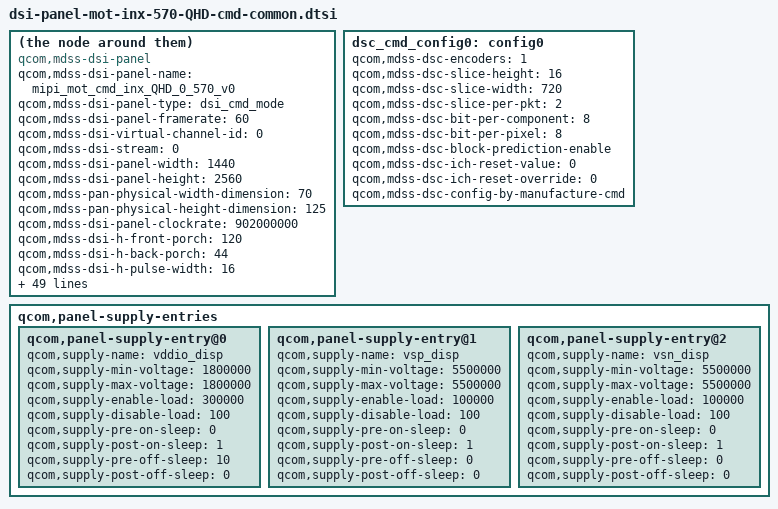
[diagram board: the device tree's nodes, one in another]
/* Copyright (c) 2015, The Linux Foundation. All rights reserved.
 *
 * This program is free software; you can redistribute it and/or modify
 * it under the terms of the GNU General Public License version 2 and
 * only version 2 as published by the Free Software Foundation.
 *
 * This program is distributed in the hope that it will be useful,
 * but WITHOUT ANY WARRANTY; without even the implied warranty of
 * MERCHANTABILITY or FITNESS FOR A PARTICULAR PURPOSE.  See the
 * GNU General Public License for more details.
 */

qcom,mdss-dsi-panel-name = "mipi_mot_cmd_inx_QHD_0_570_v0";
compatible = "qcom,mdss-dsi-panel";
qcom,mdss-dsi-panel-type = "dsi_cmd_mode";
qcom,mdss-dsi-panel-framerate = <60>;
qcom,mdss-dsi-virtual-channel-id = <0>;
qcom,mdss-dsi-stream = <0>;
qcom,mdss-dsi-panel-width = <1440>;
qcom,mdss-dsi-panel-height = <2560>;
qcom,mdss-pan-physical-width-dimension = <70>;
qcom,mdss-pan-physical-height-dimension = <125>;
qcom,mdss-dsi-panel-clockrate = <902000000>;
qcom,mdss-dsi-h-front-porch = <120>;
qcom,mdss-dsi-h-back-porch = <44>;
qcom,mdss-dsi-h-pulse-width = <16>;
qcom,mdss-dsi-h-sync-skew = <0>;
qcom,mdss-dsi-v-back-porch = <4>;
qcom,mdss-dsi-v-front-porch = <8>;
qcom,mdss-dsi-v-pulse-width = <4>;
qcom,mdss-dsi-h-left-border = <0>;
qcom,mdss-dsi-h-right-border = <0>;
qcom,mdss-dsi-v-top-border = <0>;
qcom,mdss-dsi-v-bottom-border = <0>;
qcom,mdss-dsi-bpp = <24>;
qcom,mdss-dsi-underflow-color = <0xff>;
qcom,mdss-dsi-border-color = <0>;
qcom,mdss-dsi-bllp-eof-power-mode; //todo: Check if this can be removed
qcom,mdss-dsi-lane-0-state;
qcom,mdss-dsi-lane-1-state;
qcom,mdss-dsi-lane-2-state;
qcom,mdss-dsi-lane-3-state;
qcom,mdss-dsi-tx-eot-append;

qcom,mdss-dsi-panel-timings = [EE 38 26 00 6A 6C 2C 3C 2C 03 04 00];
qcom,mdss-dsi-reset-sequence = <0 11>, <1 11>, <0 1>, <1 11>;
qcom,mdss-dsi-lp11-init;
qcom,mdss-dsi-t-clk-post = <0x2d>;
qcom,mdss-dsi-t-clk-pre = <0x2c>;
qcom,mdss-dsi-bl-max-level = <255>;
qcom,mdss-dsi-dma-trigger = "trigger_sw";
qcom,mdss-dsi-mdp-trigger = "none";
qcom,mdss-dsi-bl-pmic-control-type = "bl_ctrl_wled";
qcom,mdss-dsi-te-pin-select = <1>;
qcom,mdss-dsi-te-dcs-command = <1>;
qcom,mdss-dsi-te-check-enable;
qcom,mdss-dsi-te-using-te-pin;
qcom,mdss-dsi-on-command = [
	/* Setting VBP=8 and VFP=8 */
	39 01 00 00 00 00 04 3B 03 08 08
	/* Configure command mode */
	15 01 00 00 00 00 02 BB 10
	/* Disable BK_EN control */
	15 01 00 00 00 00 02 E5 00
	/* NVT SDC */
	15 01 00 00 00 00 02 C0 00
	/* 1600RGBX2560, GRAM Slide Parameter=16h */
	39 01 00 00 00 00 0C C9 01 01 80 00 0B 06 67 04 3A 11 F8
	/* Don't reload MTP after 0x11 cmd */
	15 01 00 00 00 00 02 FB 01
	/* CMD2 Page 4 is selected */
	15 01 00 00 00 00 02 FF 24
	/* Image up-side down & gate scan inverse */
	15 01 00 00 00 00 02 9D 36
	/* Don't reload MTP after 0x11 cmd*/
	15 01 00 00 00 00 02 FB 01
	/* Configure LEDPWM Freq ~27.48khz */
	/* CMD2 Page3 is selected */
	15 01 00 00 00 00 02 FF 23
	15 01 00 00 00 00 02 07 20
	15 01 00 00 00 00 02 08 05
	15 01 00 00 00 00 02 46 06
	/* CABC gamma adjustment */
	15 01 00 00 00 00 02 13 FF
	15 01 00 00 00 00 02 14 F5
	15 01 00 00 00 00 02 15 ED
	15 01 00 00 00 00 02 16 E5
	15 01 00 00 00 00 02 17 FF
	15 01 00 00 00 00 02 18 F2
	15 01 00 00 00 00 02 19 E5
	15 01 00 00 00 00 02 1A E5
	15 01 00 00 00 00 02 1B D8
	15 01 00 00 00 00 02 1C CC
	15 01 00 00 00 00 02 1D CC
	15 01 00 00 00 00 02 1E CC
	15 01 00 00 00 00 02 1F CC
	15 01 00 00 00 00 02 20 BF
	/* set APL_TH(1440 RGBx2560:0.225) */
	15 01 00 00 00 00 02 39 2A
	15 01 00 00 00 00 02 3B CC
	/* Don't reload MTP after 0x11 cmd*/
	15 01 00 00 00 00 02 FB 01
	/* Touch improvement - EQ Mux settings */
	/* CMD2 Page 0 is selected */
	15 01 00 00 00 00 02 FF 20
	15 01 00 00 00 00 02 5C 80
	15 01 00 00 00 00 02 5D 84
	15 01 00 00 00 00 02 62 02
	/* Program VGHO= 8.7V */
	15 01 00 00 00 00 02 0E B2
	/* Program VGLO= -5.2V */
	15 01 00 00 00 00 02 0F 92
	/* Don't reload MTP after 0x11 cmd*/
	15 01 00 00 00 00 02 FB 01
	/* CMD1 is selected */
	15 01 00 00 00 00 02 FF 10
	/* DSC configuration start */
	15 01 00 00 0a 00 02 ff 28
	15 01 00 00 0a 00 02 7a 02
	15 01 00 00 0a 00 02 fb 01
	15 01 00 00 0a 00 02 ff 10
	15 01 00 00 0a 00 02 fb 01
	15 01 00 00 0a 00 02 c0 03
	15 01 00 00 0a 00 02 bb 10
	/* DSC configuration end */

	/* 8 bits DBV = 0xFF (100%) */
	15 01 00 00 00 00 02 51 CC
	/* Write CTRL display */
	15 01 00 00 00 00 02 53 2C
	/* CABC on, UI-mode */
	15 01 00 00 00 00 02 55 01
	/* Diming Step=32, T = 1 frame */
	39 01 00 00 00 00 03 68 04 01
	/* Don't reload MTP after 0x11 cmd*/
	15 01 00 00 00 00 02 FB 01
	/* exit sleep mode */
	05 01 00 00 78 00 01 11
	/* enable_te */
	15 01 00 00 00 00 02 35 00
	/* display on */
	05 01 00 00 00 00 01 29
];

qcom,mdss-dsi-on-command-state = "dsi_lp_mode";
qcom,mdss-dsi-off-command = [
	/* display_off */
	05 01 00 00 01 00 01 28
	/* enter sleep mode */
	05 01 00 00 46 00 01 10];
qcom,mdss-dsi-off-command-state = "dsi_lp_mode";

/* Disable HBM for now*/
//qcom,mdss-dsi-hbm-on-command = [
//	/* PWM set to 100% */
//	15 01 00 00 00 00 02 51 ff];
//qcom,mdss-dsi-hbm-off-command = [
//	/* PWM set to 80% */
//	15 01 00 00 00 00 02 51 cc];

qcom,esd-check-enabled;
qcom,mdss-dsi-panel-status-check-mode = "reg_read";
qcom,mdss-dsi-panel-status-command = [06 01 00 01 00 00 01 0A];
qcom,mdss-dsi-panel-status-command-state = "dsi_hs_mode";
qcom,mdss-dsi-panel-status-value = <0x9c>;

/* Disable Dynamic CABC for now */
//qcom,mdss-dsi-cabc-ui-command = [15 01 00 00 00 00 02 55 01];
//qcom,mdss-dsi-cabc-mv-command = [15 01 00 00 00 00 02 55 03];

/* DSC Host Configuration */
qcom,compression-mode = "dsc";
qcom,config-select = <&dsc_cmd_config0>;
dsc_cmd_config0: config0 {
	qcom,mdss-dsc-encoders = <1>;
	qcom,mdss-dsc-slice-height = <16>;
	qcom,mdss-dsc-slice-width = <720>;
	qcom,mdss-dsc-slice-per-pkt = <2>;
	qcom,mdss-dsc-bit-per-component = <8>;
	qcom,mdss-dsc-bit-per-pixel = <8>;
	qcom,mdss-dsc-block-prediction-enable;
	qcom,mdss-dsc-ich-reset-value = <0>;
	qcom,mdss-dsc-ich-reset-override = <0>;
	qcom,mdss-dsc-config-by-manufacture-cmd;
};

qcom,panel-supply-entries {
	#address-cells = <1>;
	#size-cells = <0>;
	qcom,panel-supply-entry@0 {
		qcom,supply-name = "vddio_disp";
		qcom,supply-min-voltage = <1800000>;
		qcom,supply-max-voltage = <1800000>;
		qcom,supply-enable-load = <300000>;
		qcom,supply-disable-load = <100>;
		qcom,supply-pre-on-sleep = <0>;
		qcom,supply-post-on-sleep = <1>;
		qcom,supply-pre-off-sleep = <10>;
		qcom,supply-post-off-sleep = <0>;
	};
	qcom,panel-supply-entry@1 {
		qcom,supply-name = "vsp_disp";
		qcom,supply-min-voltage = <5500000>;
		qcom,supply-max-voltage = <5500000>;
		qcom,supply-enable-load = <100000>;
		qcom,supply-disable-load = <100>;
		qcom,supply-pre-on-sleep = <0>;
		qcom,supply-post-on-sleep = <1>;
		qcom,supply-pre-off-sleep = <0>;
		qcom,supply-post-off-sleep = <0>;
	};
	qcom,panel-supply-entry@2 {
		qcom,supply-name = "vsn_disp";
		qcom,supply-min-voltage = <5500000>;
		qcom,supply-max-voltage = <5500000>;
		qcom,supply-enable-load = <100000>;
		qcom,supply-disable-load = <100>;
		qcom,supply-pre-on-sleep = <0>;
		qcom,supply-post-on-sleep = <1>;
		qcom,supply-pre-off-sleep = <0>;
		qcom,supply-post-off-sleep = <0>;
	};
};
